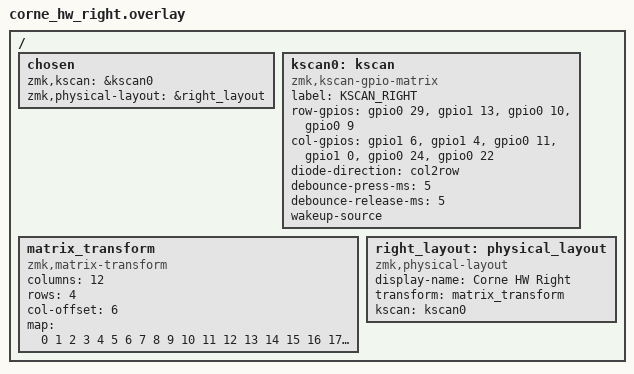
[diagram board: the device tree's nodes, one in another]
/
{
    chosen {
        zmk,kscan = &kscan0;
        zmk,physical-layout = &right_layout;
    };

    kscan0: kscan {
        compatible = "zmk,kscan-gpio-matrix";
        label = "KSCAN_RIGHT";

        /* Rows: P0.29, P1.13, P0.10, P0.09 */
        row-gpios = <&gpio0 29 (GPIO_ACTIVE_HIGH | GPIO_PULL_DOWN)>,
                    <&gpio1 13 (GPIO_ACTIVE_HIGH | GPIO_PULL_DOWN)>,
                    <&gpio0 10 (GPIO_ACTIVE_HIGH | GPIO_PULL_DOWN)>,
                    <&gpio0 9  (GPIO_ACTIVE_HIGH | GPIO_PULL_DOWN)>;

        /* Cols: P1.06, P1.04, P0.11, P1.00, P0.24, P0.22 */
        col-gpios = <&gpio1 6  GPIO_ACTIVE_HIGH>,
                    <&gpio1 4  GPIO_ACTIVE_HIGH>,
                    <&gpio0 11 GPIO_ACTIVE_HIGH>,
                    <&gpio1 0  GPIO_ACTIVE_HIGH>,
                    <&gpio0 24 GPIO_ACTIVE_HIGH>,
                    <&gpio0 22 GPIO_ACTIVE_HIGH>;

        diode-direction = "col2row";
        debounce-press-ms = <5>;
        debounce-release-ms = <5>;
        wakeup-source;
    };

    /* columns = 12 (both halves combined) and col-offset = 6 shift this
     * half's local columns 0-5 into keymap positions 6-11/18-23/etc, so
     * its key events land on the right half of the shared corne_hw.keymap
     * bindings instead of colliding with the left half's positions 0-23. */
    matrix_transform: matrix_transform {
        compatible = "zmk,matrix-transform";
        columns = <12>;
        rows = <4>;
        col-offset = <6>;
        map = <0 1 2 3 4 5  6 7 8 9 10 11  12 13 14 15 16 17  18 19 20 21 22 23>;
    };

    right_layout: physical_layout {
        compatible = "zmk,physical-layout";
        display-name = "Corne HW Right";
        transform = <&matrix_transform>;
        kscan = <&kscan0>;
    };
};

